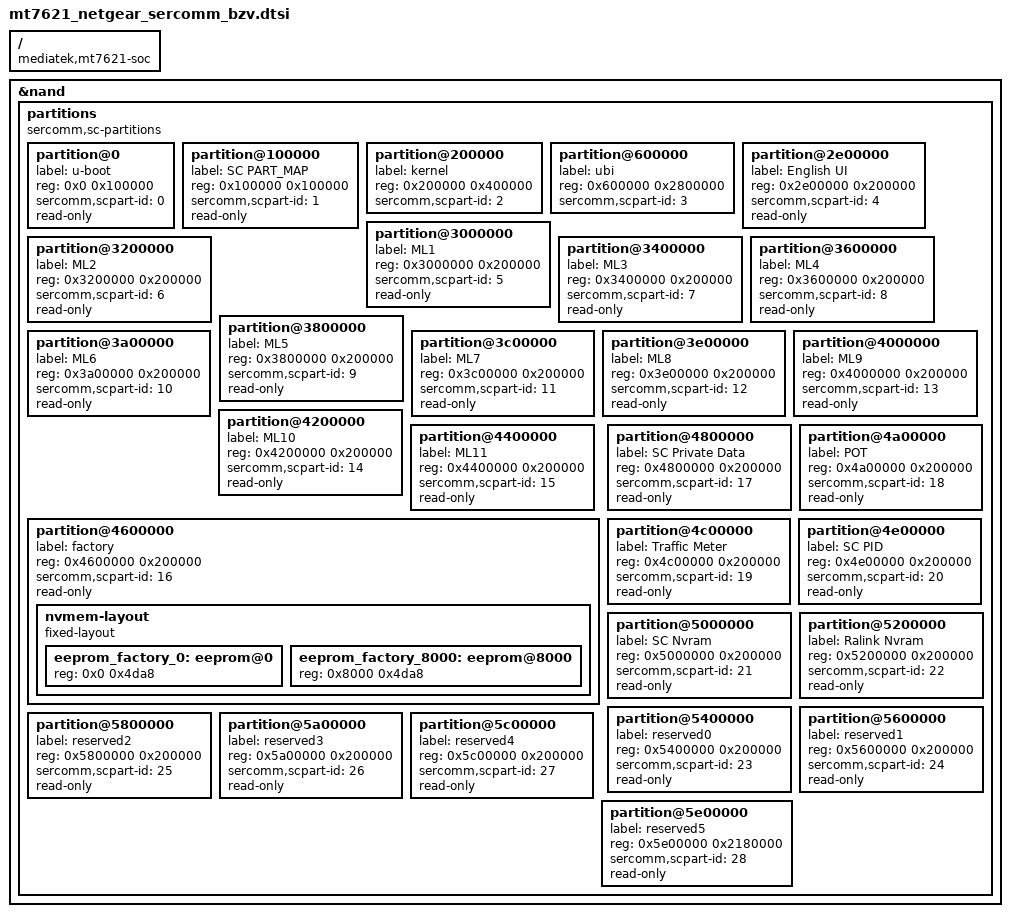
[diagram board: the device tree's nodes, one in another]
/ {
	compatible = "mediatek,mt7621-soc";
};

&nand {
	status = "okay";
	partitions {
		compatible = "sercomm,sc-partitions", "fixed-partitions";
		#address-cells = <1>;
		#size-cells = <1>;
		partition@0 {
			label = "u-boot";
			reg = <0x0 0x100000>;
			sercomm,scpart-id = <0>;
			read-only;
		};
		partition@100000 {
			label = "SC PART_MAP";
			reg = <0x100000 0x100000>;
			sercomm,scpart-id = <1>;
			read-only;
		};
		partition@200000 {
			label = "kernel";
			reg = <0x200000 0x400000>;
			sercomm,scpart-id = <2>;
		};
		partition@600000 {
			label = "ubi";
			reg = <0x600000 0x2800000>;
			sercomm,scpart-id = <3>;
		};
		partition@2e00000 {
			label = "English UI";
			reg = <0x2e00000 0x200000>;
			sercomm,scpart-id = <4>;
			read-only;
		};
		partition@3000000 {
			label = "ML1";
			reg = <0x3000000 0x200000>;
			sercomm,scpart-id = <5>;
			read-only;
		};
		partition@3200000 {
			label = "ML2";
			reg = <0x3200000 0x200000>;
			sercomm,scpart-id = <6>;
			read-only;
		};
		partition@3400000 {
			label = "ML3";
			reg = <0x3400000 0x200000>;
			sercomm,scpart-id = <7>;
			read-only;
		};
		partition@3600000 {
			label = "ML4";
			reg = <0x3600000 0x200000>;
			sercomm,scpart-id = <8>;
			read-only;
		};
		partition@3800000 {
			label = "ML5";
			reg = <0x3800000 0x200000>;
			sercomm,scpart-id = <9>;
			read-only;
		};
		partition@3a00000 {
			label = "ML6";
			reg = <0x3a00000 0x200000>;
			sercomm,scpart-id = <10>;
			read-only;
		};
		partition@3c00000 {
			label = "ML7";
			reg = <0x3c00000 0x200000>;
			sercomm,scpart-id = <11>;
			read-only;
		};
		partition@3e00000 {
			label = "ML8";
			reg = <0x3e00000 0x200000>;
			sercomm,scpart-id = <12>;
			read-only;
		};
		partition@4000000 {
			label = "ML9";
			reg = <0x4000000 0x200000>;
			sercomm,scpart-id = <13>;
			read-only;
		};
		partition@4200000 {
			label = "ML10";
			reg = <0x4200000 0x200000>;
			sercomm,scpart-id = <14>;
			read-only;
		};
		partition@4400000 {
			label = "ML11";
			reg = <0x4400000 0x200000>;
			sercomm,scpart-id = <15>;
			read-only;
		};
		partition@4600000 {
			label = "factory";
			reg = <0x4600000 0x200000>;
			sercomm,scpart-id = <16>;
			read-only;
			nvmem-layout {
				compatible = "fixed-layout";
				eeprom_factory_0: eeprom@0 {
					reg = <0x0 0x4da8>;
				};
				eeprom_factory_8000: eeprom@8000 {
					reg = <0x8000 0x4da8>;
				};
			};
		};
		partition@4800000 {
			label = "SC Private Data";
			reg = <0x4800000 0x200000>;
			sercomm,scpart-id = <17>;
			read-only;
		};
		partition@4a00000 {
			label = "POT";
			reg = <0x4a00000 0x200000>;
			sercomm,scpart-id = <18>;
			read-only;
		};
		partition@4c00000 {
			label = "Traffic Meter";
			reg = <0x4c00000 0x200000>;
			sercomm,scpart-id = <19>;
			read-only;
		};
		partition@4e00000 {
			label = "SC PID";
			reg = <0x4e00000 0x200000>;
			sercomm,scpart-id = <20>;
			read-only;
		};
		partition@5000000 {
			label = "SC Nvram";
			reg = <0x5000000 0x200000>;
			sercomm,scpart-id = <21>;
			read-only;
		};
		partition@5200000 {
			label = "Ralink Nvram";
			reg = <0x5200000 0x200000>;
			sercomm,scpart-id = <22>;
			read-only;
		};
		partition@5400000 {
			label = "reserved0";
			reg = <0x5400000 0x200000>;
			sercomm,scpart-id = <23>;
			read-only;
		};
		partition@5600000 {
			label = "reserved1";
			reg = <0x5600000 0x200000>;
			sercomm,scpart-id = <24>;
			read-only;
		};
		partition@5800000 {
			label = "reserved2";
			reg = <0x5800000 0x200000>;
			sercomm,scpart-id = <25>;
			read-only;
		};
		partition@5a00000 {
			label = "reserved3";
			reg = <0x5a00000 0x200000>;
			sercomm,scpart-id = <26>;
			read-only;
		};
		partition@5c00000 {
			label = "reserved4";
			reg = <0x5c00000 0x200000>;
			sercomm,scpart-id = <27>;
			read-only;
		};
		partition@5e00000 {
			label = "reserved5";
			reg = <0x5e00000 0x2180000>;
			sercomm,scpart-id = <28>;
			read-only;
		};
	};
};
